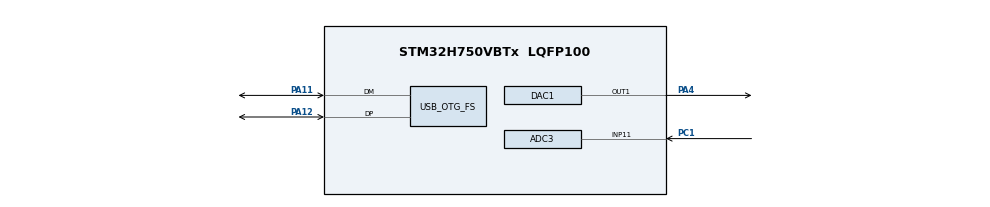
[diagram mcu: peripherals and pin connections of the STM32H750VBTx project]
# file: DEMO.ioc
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ADC3.Channel-3\#ChannelRegularConversion=ADC_CHANNEL_11
ADC3.ConversionDataManagement=ADC_CONVERSIONDATA_DMA_CIRCULAR
ADC3.EOCSelection=ADC_EOC_SEQ_CONV
ADC3.ExternalTrigConv=ADC_EXTERNALTRIG_T6_TRGO
ADC3.NbrOfConversionFlag=1
ADC3.OffsetNumber-3\#ChannelRegularConversion=ADC_OFFSET_NONE
ADC3.OffsetSignedSaturation-3\#ChannelRegularConversion=DISABLE
ADC3.Overrun=ADC_OVR_DATA_OVERWRITTEN
ADC3.Rank-3\#ChannelRegularConversion=1
ADC3.Resolution=ADC_RESOLUTION_14B
ADC3.SamplingTime-3\#ChannelRegularConversion=ADC_SAMPLETIME_2CYCLES_5
Bdma.ADC3.0.Direction=DMA_PERIPH_TO_MEMORY
Bdma.ADC3.0.EventEnable=DISABLE
Bdma.ADC3.0.Instance=BDMA_Channel0
Bdma.ADC3.0.MemDataAlignment=DMA_MDATAALIGN_HALFWORD
Bdma.ADC3.0.MemInc=DMA_MINC_ENABLE
Bdma.ADC3.0.Mode=DMA_CIRCULAR
Bdma.ADC3.0.PeriphDataAlignment=DMA_PDATAALIGN_HALFWORD
Bdma.ADC3.0.PeriphInc=DMA_PINC_DISABLE
Bdma.ADC3.0.Polarity=HAL_DMAMUX_REQ_GEN_RISING
Bdma.ADC3.0.Priority=DMA_PRIORITY_HIGH
Bdma.ADC3.0.RequestNumber=1
Bdma.ADC3.0.SignalID=NONE
Bdma.ADC3.0.SyncEnable=DISABLE
Bdma.ADC3.0.SyncPolarity=HAL_DMAMUX_SYNC_NO_EVENT
Bdma.ADC3.0.SyncRequestNumber=1
Bdma.ADC3.0.SyncSignalID=NONE
Bdma.Request0=ADC3
Bdma.RequestsNb=1
CORTEX_M7.AccessPermission_S-Cortex_Memory_Protection_Unit_Region2_Settings_S=MPU_REGION_FULL_ACCESS
CORTEX_M7.AccessPermission_Spec=MPU_REGION_FULL_ACCESS
CORTEX_M7.BaseAddress_S-Cortex_Memory_Protection_Unit_Region2_Settings_S=0x38000000
CORTEX_M7.BaseAddress_Spec=0x24000000
CORTEX_M7.CPU_DCache=Enabled
CORTEX_M7.CPU_ICache=Enabled
CORTEX_M7.DisableExec_S-Cortex_Memory_Protection_Unit_Region2_Settings_S=MPU_INSTRUCTION_ACCESS_DISABLE
CORTEX_M7.Enable_S-Cortex_Memory_Protection_Unit_Region2_Settings_S=MPU_REGION_ENABLE
CORTEX_M7.Enable_S-Cortex_Memory_Protection_Unit_Region4_Settings_S=__NULL
CORTEX_M7.Enable_Spec=__NULL
CORTEX_M7.IsShareable_Spec=MPU_ACCESS_NOT_SHAREABLE
CORTEX_M7.MPU_Control=MPU_PRIVILEGED_DEFAULT
CORTEX_M7.Size_S-Cortex_Memory_Protection_Unit_Region2_Settings_S=MPU_REGION_SIZE_32KB
CORTEX_M7.Size_Spec=MPU_REGION_SIZE_512KB
CORTEX_M7.SubRegionDisable_Spec=0x00
CORTEX_M7.TypeExtField_S-Cortex_Memory_Protection_Unit_Region2_Settings_S=MPU_TEX_LEVEL1
CORTEX_M7.TypeExtField_Spec=MPU_TEX_LEVEL1
CORTEX_M7.default_mode_Activation=1
DAC1.DAC1_OutputBuffer-DAC_OUT1=DAC_OUTPUTBUFFER_DISABLE
DAC1.DAC_Channel-DAC_OUT1=DAC_CHANNEL_1
DAC1.DAC_Trigger-DAC_OUT1=DAC_TRIGGER_T7_TRGO
DAC1.DAC_UserTrimming-DAC_OUT1=DAC_TRIMMING_FACTORY
Dma.DAC1_CH1.0.Direction=DMA_MEMORY_TO_PERIPH
Dma.DAC1_CH1.0.EventEnable=DISABLE
Dma.DAC1_CH1.0.FIFOMode=DMA_FIFOMODE_DISABLE
Dma.DAC1_CH1.0.Instance=DMA1_Stream0
Dma.DAC1_CH1.0.MemDataAlignment=DMA_MDATAALIGN_HALFWORD
Dma.DAC1_CH1.0.MemInc=DMA_MINC_ENABLE
Dma.DAC1_CH1.0.Mode=DMA_CIRCULAR
Dma.DAC1_CH1.0.PeriphDataAlignment=DMA_PDATAALIGN_HALFWORD
Dma.DAC1_CH1.0.PeriphInc=DMA_PINC_DISABLE
Dma.DAC1_CH1.0.Polarity=HAL_DMAMUX_REQ_GEN_RISING
Dma.DAC1_CH1.0.Priority=DMA_PRIORITY_HIGH
Dma.DAC1_CH1.0.RequestNumber=1
Dma.DAC1_CH1.0.SignalID=NONE
Dma.DAC1_CH1.0.SyncEnable=DISABLE
Dma.DAC1_CH1.0.SyncPolarity=HAL_DMAMUX_SYNC_NO_EVENT
Dma.DAC1_CH1.0.SyncRequestNumber=1
Dma.DAC1_CH1.0.SyncSignalID=NONE
Dma.Request0=DAC1_CH1
Mcu.Family=STM32H7
Mcu.Name=STM32H750VBTx
Mcu.Package=LQFP100
NVIC.BDMA_Channel0_IRQn=true\:0\:0\:false\:false\:true\:false\:true\:true
NVIC.DMA1_Stream0_IRQn=true\:0\:0\:false\:false\:true\:false\:true\:true
NVIC.OTG_FS_IRQn=true\:0\:0\:false\:false\:true\:false\:true\:true
NVIC.PriorityGroup=NVIC_PRIORITYGROUP_4
NVIC.TIM8_TRG_COM_TIM14_IRQn=true\:0\:0\:false\:false\:true\:true\:true\:true
PA11.Mode=Device_Only
PA11.Signal=USB_OTG_FS_DM
PA12.Mode=Device_Only
PA12.Signal=USB_OTG_FS_DP
PA13\ (JTMS/SWDIO).Mode=Serial_Wire
PA13\ (JTMS/SWDIO).Signal=DEBUG_JTMS-SWDIO
PA14\ (JTCK/SWCLK).Mode=Serial_Wire
PA14\ (JTCK/SWCLK).Signal=DEBUG_JTCK-SWCLK
PA4.Signal=COMP_DAC11_group
PC1.Signal=ADCx_INP11
PC14-OSC32_IN\ (OSC32_IN).Mode=LSE-External-Oscillator
PC14-OSC32_IN\ (OSC32_IN).Signal=RCC_OSC32_IN
PC15-OSC32_OUT\ (OSC32_OUT).Mode=LSE-External-Oscillator
PC15-OSC32_OUT\ (OSC32_OUT).Signal=RCC_OSC32_OUT
PH0-OSC_IN\ (PH0).Mode=HSE-External-Oscillator
PH0-OSC_IN\ (PH0).Signal=RCC_OSC_IN
PH1-OSC_OUT\ (PH1).Mode=HSE-External-Oscillator
PH1-OSC_OUT\ (PH1).Signal=RCC_OSC_OUT
ProjectManager.HeapSize=0x2000
ProjectManager.StackSize=0x400
ProjectManager.TargetToolchain=MDK-ARM V5.32
RCC.ADCFreq_Value=50000000
RCC.APB1Freq_Value=120000000
RCC.APB2Freq_Value=120000000
RCC.APB3Freq_Value=120000000
RCC.APB4Freq_Value=120000000
RCC.CortexFreq_Value=480000000
RCC.D1PPRE=RCC_APB3_DIV2
RCC.D2PPRE1=RCC_APB1_DIV2
RCC.D2PPRE2=RCC_APB2_DIV2
RCC.D3PPRE=RCC_APB4_DIV2
RCC.DIVM1=5
RCC.DIVM2=5
RCC.DIVN1=192
RCC.DIVN2=20
RCC.DIVQ1=15
RCC.EnbaleCSS=true
RCC.HCLKFreq_Value=240000000
RCC.HPRE=RCC_HCLK_DIV2
RCC.PLL2FRACN=0
RCC.PLL3FRACN=0
RCC.PLLFRACN=0
RCC.PLLSourceVirtual=RCC_PLLSOURCE_HSE
RCC.SYSCLKFreq_VALUE=480000000
RCC.SYSCLKSource=RCC_SYSCLKSOURCE_PLLCLK
RCC.USBCLockSelection=RCC_USBCLKSOURCE_HSI48
RCC.USBFreq_Value=48000000
SH.ADCx_INP11.0=ADC3_INP11,IN11-Single-Ended
SH.COMP_DAC11_group.0=DAC1_OUT1,DAC_OUT1
TIM14.AutoReloadPreload=TIM_AUTORELOAD_PRELOAD_ENABLE
TIM14.Period=240-1
TIM14.Prescaler=1000-1
TIM6.AutoReloadPreload=TIM_AUTORELOAD_PRELOAD_ENABLE
TIM6.Period=120-1
TIM6.TIM_MasterOutputTrigger=TIM_TRGO_UPDATE
TIM7.AutoReloadPreload=TIM_AUTORELOAD_PRELOAD_ENABLE
TIM7.Period=240-1
TIM7.TIM_MasterOutputTrigger=TIM_TRGO_UPDATE
USB_DEVICE.CLASS_NAME_FS=CDC
USB_DEVICE.VirtualMode-CDC_FS=Cdc
USB_DEVICE.VirtualModeFS=Cdc_FS
USB_OTG_FS.VirtualMode=Device_Only
USB_OTG_FS.dma_enable=DISABLE
VP_MEMORYMAP_VS_MEMORYMAP.Mode=CurAppReg
VP_TIM14_VS_ClockSourceINT.Mode=Enable_Timer
VP_TIM6_VS_ClockSourceINT.Mode=Enable_Timer
VP_TIM7_VS_ClockSourceINT.Mode=Enable_Timer
VP_USB_DEVICE_VS_USB_DEVICE_CDC_FS.Mode=CDC_FS
board=custom

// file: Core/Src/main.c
/* USER CODE BEGIN Header */
/**
  ******************************************************************************
  * @file           : main.c
  * @brief          : Main program body
  ******************************************************************************
  * @attention
  *
  * Copyright (c) 2025 STMicroelectronics.
  * All rights reserved.
  *
  * This software is licensed under terms that can be found in the LICENSE file
  * in the root directory of this software component.
  * If no LICENSE file comes with this software, it is provided AS-IS.
  *
  ******************************************************************************
  */
/* USER CODE END Header */
#include "main.h"
#include "adc.h"
#include "bdma.h"
#include "dac.h"
#include "dma.h"
#include "memorymap.h"
#include "tim.h"
#include "usb_device.h"
#include "gpio.h"

/* USER CODE BEGIN Includes */

#include "usbd_cdc_if.h"
#include "myusb.h"
#include "mytime.h"
#include "const.h"
#include "math.h"
#include "myadc.h"
#include "mydac.h"

/* USER CODE END Includes */

/* USER CODE BEGIN PV */
extern JustFloatVofa adc_frame;

/* USER CODE END PV */

void SystemClock_Config(void);
static void MPU_Config(void);

int main(void)
{

  /* MPU Configuration--------------------------------------------------------*/
  MPU_Config();

  /* Enable the CPU Cache */

  /* Enable I-Cache---------------------------------------------------------*/
  SCB_EnableICache();

  /* Enable D-Cache---------------------------------------------------------*/
  SCB_EnableDCache();

  /* MCU Configuration--------------------------------------------------------*/

  /* Reset of all peripherals, Initializes the Flash interface and the Systick. */
  HAL_Init();

  /* Configure the system clock */
  SystemClock_Config();

  /* Initialize all configured peripherals */
  MX_GPIO_Init();
  MX_BDMA_Init();
  MX_DMA_Init();
  MX_USB_DEVICE_Init();
  MX_ADC3_Init();
  MX_TIM14_Init();
  MX_TIM6_Init();
  MX_DAC1_Init();
  MX_TIM7_Init();
  /* USER CODE BEGIN 2 */

  JustFloatVofa_init(&adc_frame);

  //mytime_start(&htim14);

  mydac_set_data();
  mydac_start_out();
  ADC_DMA_Start();
  /* USER CODE END 2 */

  /* Infinite loop */
  while (1)
  {

    /* USER CODE BEGIN 3 */
		usb_send_adc3_data();
    //USB_printf("Hello USB CDC!\r\n");
	  // JustFloatVofa_setData(&adc_frame, adc_frame_values1,adc_frame_values2,DATA_LEN_MAX);
    // JustFloatVofa_send(&adc_frame);
    // HAL_Delay(1);

  }
  /* USER CODE END 3 */
}

void SystemClock_Config(void)
{
  RCC_OscInitTypeDef RCC_OscInitStruct = {0};
  RCC_ClkInitTypeDef RCC_ClkInitStruct = {0};

  /** Supply configuration update enable
  */
  HAL_PWREx_ConfigSupply(PWR_LDO_SUPPLY);

  /** Configure the main internal regulator output voltage
  */
  __HAL_PWR_VOLTAGESCALING_CONFIG(PWR_REGULATOR_VOLTAGE_SCALE1);

  while(!__HAL_PWR_GET_FLAG(PWR_FLAG_VOSRDY)) {}

  __HAL_RCC_SYSCFG_CLK_ENABLE();
  __HAL_PWR_VOLTAGESCALING_CONFIG(PWR_REGULATOR_VOLTAGE_SCALE0);

  while(!__HAL_PWR_GET_FLAG(PWR_FLAG_VOSRDY)) {}

  /** Initializes the RCC Oscillators according to the specified parameters
  * in the RCC_OscInitTypeDef structure.
  */
  RCC_OscInitStruct.OscillatorType = RCC_OSCILLATORTYPE_HSI48|RCC_OSCILLATORTYPE_HSE;
  RCC_OscInitStruct.HSEState = RCC_HSE_ON;
  RCC_OscInitStruct.HSI48State = RCC_HSI48_ON;
  RCC_OscInitStruct.PLL.PLLState = RCC_PLL_ON;
  RCC_OscInitStruct.PLL.PLLSource = RCC_PLLSOURCE_HSE;
  RCC_OscInitStruct.PLL.PLLM = 5;
  RCC_OscInitStruct.PLL.PLLN = 192;
  RCC_OscInitStruct.PLL.PLLP = 2;
  RCC_OscInitStruct.PLL.PLLQ = 15;
  RCC_OscInitStruct.PLL.PLLR = 2;
  RCC_OscInitStruct.PLL.PLLRGE = RCC_PLL1VCIRANGE_2;
  RCC_OscInitStruct.PLL.PLLVCOSEL = RCC_PLL1VCOWIDE;
  RCC_OscInitStruct.PLL.PLLFRACN = 0;
  if (HAL_RCC_OscConfig(&RCC_OscInitStruct) != HAL_OK)
  {
    Error_Handler();
  }

  /** Initializes the CPU, AHB and APB buses clocks
  */
  RCC_ClkInitStruct.ClockType = RCC_CLOCKTYPE_HCLK|RCC_CLOCKTYPE_SYSCLK
                              |RCC_CLOCKTYPE_PCLK1|RCC_CLOCKTYPE_PCLK2
                              |RCC_CLOCKTYPE_D3PCLK1|RCC_CLOCKTYPE_D1PCLK1;
  RCC_ClkInitStruct.SYSCLKSource = RCC_SYSCLKSOURCE_PLLCLK;
  RCC_ClkInitStruct.SYSCLKDivider = RCC_SYSCLK_DIV1;
  RCC_ClkInitStruct.AHBCLKDivider = RCC_HCLK_DIV2;
  RCC_ClkInitStruct.APB3CLKDivider = RCC_APB3_DIV2;
  RCC_ClkInitStruct.APB1CLKDivider = RCC_APB1_DIV2;
  RCC_ClkInitStruct.APB2CLKDivider = RCC_APB2_DIV2;
  RCC_ClkInitStruct.APB4CLKDivider = RCC_APB4_DIV2;

  if (HAL_RCC_ClockConfig(&RCC_ClkInitStruct, FLASH_LATENCY_4) != HAL_OK)
  {
    Error_Handler();
  }

  /** Enables the Clock Security System
  */
  HAL_RCC_EnableCSS();
}

 /* MPU Configuration */

void MPU_Config(void)
{
  MPU_Region_InitTypeDef MPU_InitStruct = {0};

  /* Disables the MPU */
  HAL_MPU_Disable();

  /** Initializes and configures the Region and the memory to be protected
  */
  MPU_InitStruct.Enable = MPU_REGION_ENABLE;
  MPU_InitStruct.BaseAddress = 0x38000000;
  MPU_InitStruct.Size = MPU_REGION_SIZE_32KB;
  MPU_InitStruct.SubRegionDisable = 0x0;
  MPU_InitStruct.TypeExtField = MPU_TEX_LEVEL1;
  MPU_InitStruct.AccessPermission = MPU_REGION_FULL_ACCESS;
  MPU_InitStruct.DisableExec = MPU_INSTRUCTION_ACCESS_DISABLE;
  MPU_InitStruct.IsShareable = MPU_ACCESS_NOT_SHAREABLE;
  MPU_InitStruct.IsCacheable = MPU_ACCESS_NOT_CACHEABLE;
  MPU_InitStruct.IsBufferable = MPU_ACCESS_NOT_BUFFERABLE;

  HAL_MPU_ConfigRegion(&MPU_InitStruct);
  /* Enables the MPU */
  HAL_MPU_Enable(MPU_PRIVILEGED_DEFAULT);

}

void Error_Handler(void)
{
  __disable_irq();
  while (1)
  {
  }
}
